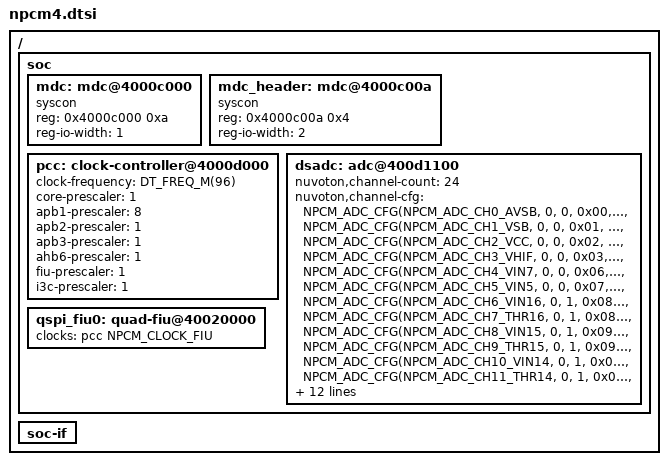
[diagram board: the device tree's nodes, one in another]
/*
 * Copyright (c) 2024 Nuvoton Technology Corporation.
 *
 * SPDX-License-Identifier: Apache-2.0
 */

/* Device tree declarations of npcm soc family */
#include "npcm.dtsi"
#include "npcm4/npcm4-pincfg-default.dtsi"
#include "npcm4/npcm4-pinctrl.dtsi"
#include "npcm4/npcm4-miwus-int-map.dtsi"
#include <freq.h>

/ {
	soc {

		mdc: mdc@4000c000 {
			compatible = "syscon";
			reg = <0x4000c000 0xa>;
			reg-io-width = <1>;
		};

		mdc_header: mdc@4000c00a {
			compatible = "syscon";
			reg = <0x4000c00a 0x4>;
			reg-io-width = <2>;
		};

		pcc: clock-controller@4000d000 {
			clock-frequency = <DT_FREQ_M(96)>; /* OFMCLK runs at 96MHz */
			core-prescaler = <1>; /* CORE_CLK runs at 96MHz */
			apb1-prescaler = <8>; /* APB1_CLK runs at 12MHz */
			apb2-prescaler = <1>; /* APB2_CLK runs at 96MHz */
			apb3-prescaler = <1>; /* APB3_CLK runs at 96MHz */
			ahb6-prescaler = <1>; /* APB6_CLK runs at 96MHz */
			fiu-prescaler = <1>; /* FIU_CLK runs at 96MHz */
			i3c-prescaler = <1>; /* I3C_CLK runs at 96MHz */
		};

		dsadc: adc@400d1100 {
			nuvoton,channel-count = <24>;
			nuvoton,channel-cfg = <NPCM_ADC_CFG(NPCM_ADC_CH0_AVSB, 0, 0, 0x00, 0, 0)>,
					<NPCM_ADC_CFG(NPCM_ADC_CH1_VSB, 0, 0, 0x01, 0, 0)>,
					<NPCM_ADC_CFG(NPCM_ADC_CH2_VCC, 0, 0, 0x02, 0, 0)>,
					<NPCM_ADC_CFG(NPCM_ADC_CH3_VHIF, 0, 0, 0x03, 0, 0)>,
					<NPCM_ADC_CFG(NPCM_ADC_CH4_VIN7, 0, 0, 0x06, 0, 0)>,
					<NPCM_ADC_CFG(NPCM_ADC_CH5_VIN5, 0, 0, 0x07, 0, 0)>,
					<NPCM_ADC_CFG(NPCM_ADC_CH6_VIN16, 0, 1, 0x08, 0, 1)>,
					<NPCM_ADC_CFG(NPCM_ADC_CH7_THR16, 0, 1, 0x08, 0, 0)>,
					<NPCM_ADC_CFG(NPCM_ADC_CH8_VIN15, 0, 1, 0x09, 1, 1)>,
					<NPCM_ADC_CFG(NPCM_ADC_CH9_THR15, 0, 1, 0x09, 1, 0)>,
					<NPCM_ADC_CFG(NPCM_ADC_CH10_VIN14, 0, 1, 0x0A, 2, 1)>,
					<NPCM_ADC_CFG(NPCM_ADC_CH11_THR14, 0, 1, 0x0A, 2, 0)>,
					<NPCM_ADC_CFG(NPCM_ADC_CH12_VIN1, 0, 1, 0x0B, 3, 1)>,
					<NPCM_ADC_CFG(NPCM_ADC_CH13_THR1, 0, 1, 0x0B, 3, 0)>,
					<NPCM_ADC_CFG(NPCM_ADC_CH14_VIN2, 0, 1, 0x0C, 4, 1)>,
					<NPCM_ADC_CFG(NPCM_ADC_CH15_THR2, 0, 1, 0x0C, 4, 0)>,
					<NPCM_ADC_CFG(NPCM_ADC_CH16_VIN3, 0, 0, 0x0D, 0, 0)>,
					<NPCM_ADC_CFG(NPCM_ADC_CH17_VTT, 0, 0, 0x0E, 0, 0)>,
					<NPCM_ADC_CFG(NPCM_ADC_CH18_VBAT, 0, 0, 0x0F, 0, 0)>,
					<NPCM_ADC_CFG(NPCM_ADC_CH19_TD2P, 1, 0, 0x00, 0, 0)>,
					<NPCM_ADC_CFG(NPCM_ADC_CH20_TD1P, 1, 0, 0x01, 0, 0)>,
					<NPCM_ADC_CFG(NPCM_ADC_CH21_TD0P, 1, 0, 0x02, 0, 0)>,
					<NPCM_ADC_CFG(NPCM_ADC_CH22_TD3P, 1, 0, 0x03, 0, 0)>,
					<NPCM_ADC_CFG(NPCM_ADC_CH23_TD4P, 1, 0, 0x04, 0, 0)>;
		};

		qspi_fiu0: quad-fiu@40020000 {
			clocks = <&pcc NPCM_CLOCK_FIU>;
		};
	};

	soc-if {
	};
};
